# Qorvo_SVD register map
Vendor: Qorvo Inc; Series: ARMCM4; File version: 1.0
Registers are 8-bit, read-write, reset 0x0 unless marked. A register's access mark holds for its fields unless they carry their own. Offsets are from the block's base; [hi:lo] are bit positions; {n}, {i} and the like mark numbered series.

## IOB
Base 0x40000700
0x00 IOB_0X00000000
  [7:0] DBG0_SEL — selects internal signal to see on dbg0
0x01 IOB_0X00000001
  [7:0] DBG1_SEL — selects internal signal to see on dbg1
0x02 IOB_0X00000002
  [7:0] DBG2_SEL — selects internal signal to see on dbg2
0x03 IOB_0X00000003
  [7:0] DBG3_SEL — selects internal signal to see on dbg3
0x04 IOB_0X00000004
  [7:0] DBG4_SEL — selects internal signal to see on dbg4
0x05 IOB_0X00000005
  [7:0] DBG5_SEL — selects internal signal to see on dbg5
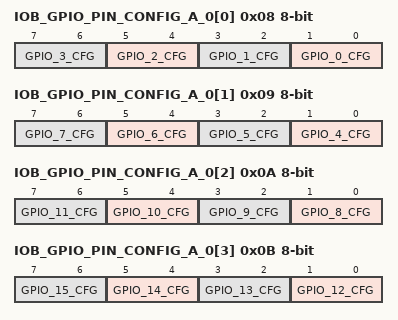
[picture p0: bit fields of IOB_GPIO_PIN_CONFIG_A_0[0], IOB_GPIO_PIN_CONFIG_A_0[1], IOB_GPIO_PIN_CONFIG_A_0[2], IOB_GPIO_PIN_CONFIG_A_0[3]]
0x08 IOB_GPIO_PIN_CONFIG_A_0[0]
  [2n+1:2n] GPIO_{n}_CFG (n=0..3) — pull up, pull down, buskeeper configuration
0x09 IOB_GPIO_PIN_CONFIG_A_0[1]
  [2n-7:2n-8] GPIO_{n}_CFG (n=4..7) — pull up, pull down, buskeeper configuration
0x0A IOB_GPIO_PIN_CONFIG_A_0[2]
  [2n-15:2n-16] GPIO_{n}_CFG (n=8..11) — pull up, pull down, buskeeper configuration
0x0B IOB_GPIO_PIN_CONFIG_A_0[3]
  [2n-23:2n-24] GPIO_{n}_CFG (n=12..15) — pull up, pull down, buskeeper configuration
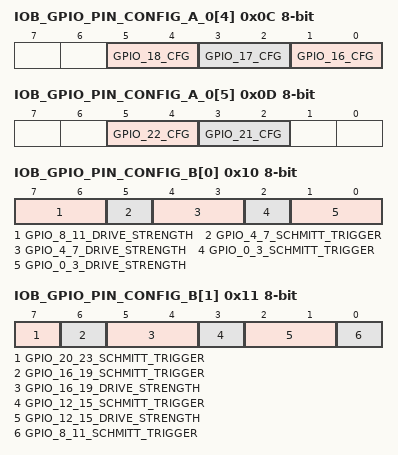
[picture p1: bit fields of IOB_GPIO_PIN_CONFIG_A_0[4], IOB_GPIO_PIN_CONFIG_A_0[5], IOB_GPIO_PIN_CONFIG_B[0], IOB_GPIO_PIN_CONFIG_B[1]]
0x0C IOB_GPIO_PIN_CONFIG_A_0[4]
  [5:4] GPIO_18_CFG — pull up, pull down, buskeeper configuration
  [3:2] GPIO_17_CFG — pull up, pull down, buskeeper configuration
  [1:0] GPIO_16_CFG — pull up, pull down, buskeeper configuration
0x0D IOB_GPIO_PIN_CONFIG_A_0[5]
  [5:4] GPIO_22_CFG — pull up, pull down, buskeeper configuration
  [3:2] GPIO_21_CFG — pull up, pull down, buskeeper configuration
0x10 IOB_GPIO_PIN_CONFIG_B[0]
  [7:6] GPIO_8_11_DRIVE_STRENGTH — drive strength 00 = 4.5mA, 01 = 9mA, 10 = 13.5mA, 11 = 18mA
  [5] GPIO_4_7_SCHMITT_TRIGGER — Schmitt trigger enable
  [4:3] GPIO_4_7_DRIVE_STRENGTH — drive strength 00 = 4.5mA, 01 = 9mA, 10 = 13.5mA, 11 = 18mA
  [2] GPIO_0_3_SCHMITT_TRIGGER — Schmitt trigger enable
  [1:0] GPIO_0_3_DRIVE_STRENGTH — drive strength 00 = 4.5mA, 01 = 9mA, 10 = 13.5mA, 11 = 18mA
0x11 IOB_GPIO_PIN_CONFIG_B[1]
  [7] GPIO_20_23_SCHMITT_TRIGGER — Schmitt trigger enable
  [6] GPIO_16_19_SCHMITT_TRIGGER — Schmitt trigger enable
  [5:4] GPIO_16_19_DRIVE_STRENGTH — drive strength 00 = 4.5mA, 01 = 9mA, 10 = 13.5mA, 11 = 18mA
  [3] GPIO_12_15_SCHMITT_TRIGGER — Schmitt trigger enable
  [2:1] GPIO_12_15_DRIVE_STRENGTH — drive strength 00 = 4.5mA, 01 = 9mA, 10 = 13.5mA, 11 = 18mA
  [0] GPIO_8_11_SCHMITT_TRIGGER — Schmitt trigger enable
0x12 IOB_GPIO_PIN_CONFIG_B[2]
  [1:0] GPIO_20_23_DRIVE_STRENGTH — drive strength 00 = 4.5mA, 01 = 9mA, 10 = 13.5mA, 11 = 18mA
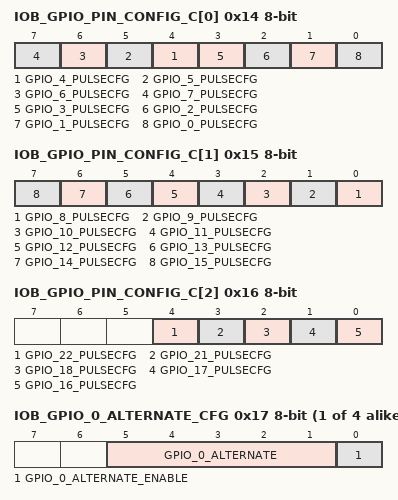
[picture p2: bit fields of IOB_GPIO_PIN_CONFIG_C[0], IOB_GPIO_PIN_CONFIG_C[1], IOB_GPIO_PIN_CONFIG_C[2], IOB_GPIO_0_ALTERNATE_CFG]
0x14 IOB_GPIO_PIN_CONFIG_C[0]
  [n] GPIO_{n}_PULSECFG (n=4..7) — Enables a pullup in the iocell that can be activated in a duty cycled way (also during sleep). The signal activating the pull up is generated in the pmud (setting gpio_pu_pulse_period)
  [3] GPIO_3_PULSECFG — Enables a strong driver in the iocell that can be activated in a duty cycled way (also during sleep). The signal activating the strong driver is generated in the pmud (setting gpio_pu_pulse_period)
  [2] GPIO_2_PULSECFG — Enables a pullup in the iocell that can be activated in a duty cycled way (also during sleep). The signal activating the pull up is generated in the pmud (setting gpio_pu_pulse_period)
  [1] GPIO_1_PULSECFG — Enables a strong driver in the iocell that can be activated in a duty cycled way (also during sleep). The signal activating the strong driver is generated in the pmud (setting gpio_pu_pulse_period)
  [0] GPIO_0_PULSECFG — Enables a pullup in the iocell that can be activated in a duty cycled way (also during sleep). The signal activating the pull up is generated in the pmud (setting gpio_pu_pulse_period)
0x15 IOB_GPIO_PIN_CONFIG_C[1]
  [n-8] GPIO_{n}_PULSECFG (n=8..15) — Enables a pullup in the iocell that can be activated in a duty cycled way (also during sleep). The signal activating the pull up is generated in the pmud (setting gpio_pu_pulse_period)
0x16 IOB_GPIO_PIN_CONFIG_C[2]
  [4] GPIO_22_PULSECFG — Enables a pullup in the iocell that can be activated in a duty cycled way (also during sleep). The signal activating the pull up is generated in the pmud (setting gpio_pu_pulse_period)
  [3] GPIO_21_PULSECFG — Enables a pullup in the iocell that can be activated in a duty cycled way (also during sleep). The signal activating the pull up is generated in the pmud (setting gpio_pu_pulse_period)
  [2] GPIO_18_PULSECFG — Enables a strong driver in the iocell that can be activated in a duty cycled way (also during sleep). The signal activating the strong driver is generated in the pmud (setting gpio_pu_pulse_period)
  [1] GPIO_17_PULSECFG — Enables a pullup in the iocell that can be activated in a duty cycled way (also during sleep). The signal activating the pull up is generated in the pmud (setting gpio_pu_pulse_period)
  [0] GPIO_16_PULSECFG — Enables a strong driver in the iocell that can be activated in a duty cycled way (also during sleep). The signal activating the strong driver is generated in the pmud (setting gpio_pu_pulse_period)
{0x17+i} IOB_GPIO_{i}_ALTERNATE_CFG (i=0..3)
  [5:1] GPIO_{i}_ALTERNATE, [0] GPIO_{i}_ALTERNATE_ENABLE
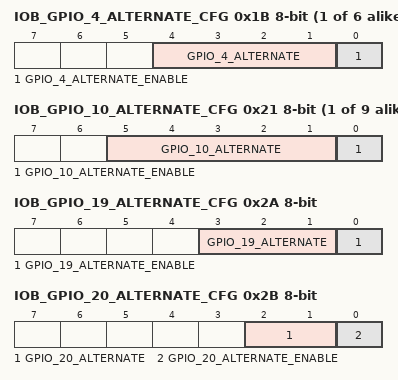
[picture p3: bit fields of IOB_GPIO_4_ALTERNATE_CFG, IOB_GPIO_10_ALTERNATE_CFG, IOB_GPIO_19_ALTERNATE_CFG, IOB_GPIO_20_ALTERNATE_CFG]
{0x17+i} IOB_GPIO_{i}_ALTERNATE_CFG (i=4..9)
  [4:1] GPIO_{i}_ALTERNATE, [0] GPIO_{i}_ALTERNATE_ENABLE
{0x17+i} IOB_GPIO_{i}_ALTERNATE_CFG (i=10..18)
  [5:1] GPIO_{i}_ALTERNATE, [0] GPIO_{i}_ALTERNATE_ENABLE
0x2A IOB_GPIO_19_ALTERNATE_CFG
  [3:1] GPIO_19_ALTERNATE, [0] GPIO_19_ALTERNATE_ENABLE
0x2B IOB_GPIO_20_ALTERNATE_CFG
  [2:1] GPIO_20_ALTERNATE, [0] GPIO_20_ALTERNATE_ENABLE
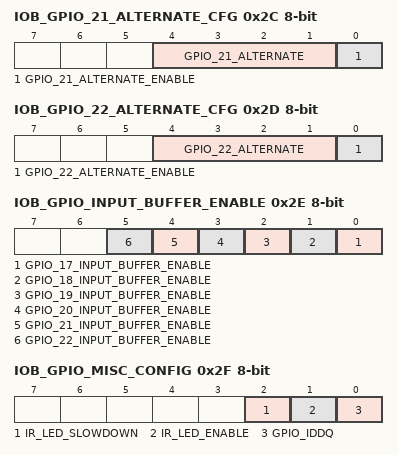
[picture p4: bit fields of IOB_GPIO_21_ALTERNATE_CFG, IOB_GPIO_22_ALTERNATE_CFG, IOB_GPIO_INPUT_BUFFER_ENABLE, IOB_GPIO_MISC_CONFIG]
0x2C IOB_GPIO_21_ALTERNATE_CFG
  [4:1] GPIO_21_ALTERNATE, [0] GPIO_21_ALTERNATE_ENABLE
0x2D IOB_GPIO_22_ALTERNATE_CFG
  [4:1] GPIO_22_ALTERNATE, [0] GPIO_22_ALTERNATE_ENABLE
0x2E IOB_GPIO_INPUT_BUFFER_ENABLE
  [n-17] GPIO_{n}_INPUT_BUFFER_ENABLE (n=17..22) — enables/disables the input buffer on gpio {n}. Disabling the buffer supplies isolation for when the pad is used for something else.
0x2F IOB_GPIO_MISC_CONFIG
  [2] IR_LED_SLOWDOWN — Reduces drive-strength to high drive IR pad
  [1] IR_LED_ENABLE — Enables a high drive (sink) on ir pad
  [0] GPIO_IDDQ — controls the iddq input of the gpios
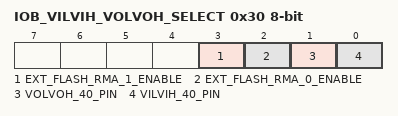
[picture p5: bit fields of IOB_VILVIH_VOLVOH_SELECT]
0x30 IOB_VILVIH_VOLVOH_SELECT
  [3] EXT_FLASH_RMA_1_ENABLE — Enables the rma interface for type 1 external flash
  [2] EXT_FLASH_RMA_0_ENABLE — Enables the rma interface for type 0 external flash
  [1] VOLVOH_40_PIN — Select 40 pin volvoh mode
  [0] VILVIH_40_PIN — Select 40 pin vilvih mode
0x31 IOB_0X00000031 ro
  [5:0] DEBUG_STATUS — Reflects the values on the debug bus
